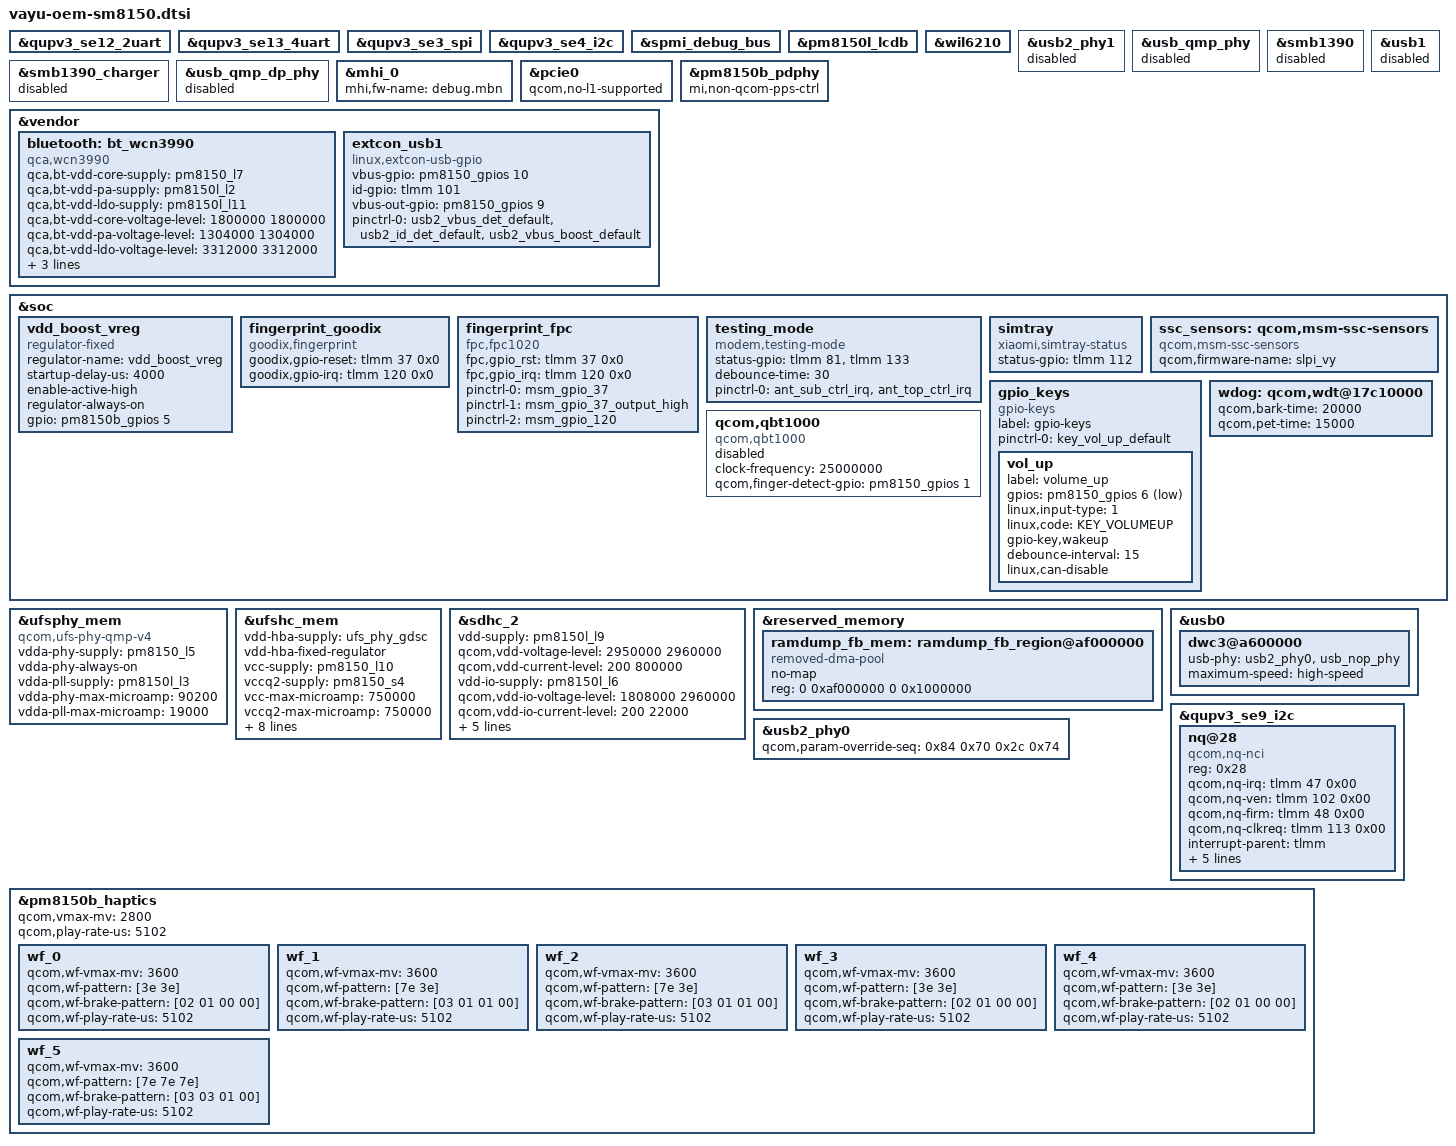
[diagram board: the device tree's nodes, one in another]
/* Copyright (c) 2017-2018, The Linux Foundation. All rights reserved.
 *
 * This program is free software; you can redistribute it and/or modify
 * it under the terms of the GNU General Public License version 2 and
 * only version 2 as published by the Free Software Foundation.
 *
 * This program is distributed in the hope that it will be useful,
 * but WITHOUT ANY WARRANTY; without even the implied warranty of
 * MERCHANTABILITY or FITNESS FOR A PARTICULAR PURPOSE.  See the
 * GNU General Public License for more details.
 */

#include <dt-bindings/gpio/gpio.h>
#include <dt-bindings/input/input.h>

#include "../../sm8150-pmic-overlay.dtsi"
#include "../../sm8150-sde-display.dtsi"

#include "vayu-oem-audio-overlay.dtsi"
#include "vayu-oem-thermal-overlay.dtsi"
#include "vayu-oem-touchscreen-overlay.dtsi"
#include "vayu-oem-sde-overlay.dtsi"
#include "vayu-oem-charger.dtsi"
#include "vayu-oem-leds.dtsi"

#include "vayu-oem-pinctrl.dtsi"
#include "vayu-oem-sm8150-camera-sensor-mtp.dtsi"

&qupv3_se12_2uart {
	status = "ok";
};

&qupv3_se13_4uart {
	status = "ok";
};

&qupv3_se3_spi {
	status = "ok";
};

&qupv3_se4_i2c {
	status = "ok";
};

&spmi_debug_bus {
	status = "ok";
};

&pm8150l_lcdb {
	status = "ok";
};

&wil6210 {
	status = "ok";
};

&usb2_phy1 {
	status = "ok";
};

&usb_qmp_phy {
	status = "ok";
};

&smb1390 {
	status = "disabled";
};

&smb1390_charger {
	status = "disabled";
};

&usb_qmp_dp_phy {
	status = "disabled";
};

&usb1 {
	status = "disabled";
};

&usb2_phy1 {
	status = "disabled";
};

&usb_qmp_phy {
	status = "disabled";
};

&mhi_0 {
	mhi,fw-name = "debug.mbn";
};

&pcie0 {
	qcom,no-l1-supported;
};

&pm8150b_pdphy {
	mi,non-qcom-pps-ctrl;
};

&vendor {

	bluetooth: bt_wcn3990 {
		compatible = "qca,wcn3990";
		qca,bt-vdd-core-supply = <&pm8150_l7>;
		qca,bt-vdd-pa-supply = <&pm8150l_l2>;
		qca,bt-vdd-ldo-supply = <&pm8150l_l11>;

		qca,bt-vdd-core-voltage-level = <1800000 1800000>;
		qca,bt-vdd-pa-voltage-level = <1304000 1304000>;
		qca,bt-vdd-ldo-voltage-level = <3312000 3312000>;

		qca,bt-vdd-core-current-level = <0>; /* LPM/PFM */
		qca,bt-vdd-pa-current-level = <0>; /* LPM/PFM */
		qca,bt-vdd-ldo-current-level = <0>; /* LPM/PFM */
	};

	extcon_usb1: extcon_usb1 {
		compatible = "linux,extcon-usb-gpio";
		vbus-gpio = <&pm8150_gpios 10 GPIO_ACTIVE_HIGH>;
		id-gpio = <&tlmm 101 GPIO_ACTIVE_HIGH>;
		vbus-out-gpio = <&pm8150_gpios 9 GPIO_ACTIVE_HIGH>;

		pinctrl-names = "default";
		pinctrl-0 = <&usb2_vbus_det_default
			     &usb2_id_det_default
			     &usb2_vbus_boost_default>;
	};
};

&soc {

	vdd_boost_vreg: vdd_boost_vreg {
		compatible = "regulator-fixed";
		regulator-name = "vdd_boost_vreg";
		startup-delay-us = <4000>;
		enable-active-high;
		regulator-always-on;
		gpio = <&pm8150b_gpios 5 0>;
	 };

	fingerprint_goodix {
		compatible = "goodix,fingerprint";
		goodix,gpio-reset = <&tlmm 37 0x0>;
		goodix,gpio-irq = <&tlmm 120 0x0>;
		//goodix.gpio_pwr = <&tlmm 125 0x0>;
		//fp_vdd_vreg = <&pm8150l_l7>;
		status = "ok";
	};

	fingerprint_fpc {
			compatible = "fpc,fpc1020";
			fpc,gpio_rst    = <&tlmm 37 0x0>;
			fpc,gpio_irq    = <&tlmm 120 0x0>;
			pinctrl-names = "fpc1020_reset_reset",
					"fpc1020_reset_active",
					"fpc1020_irq_active";

			pinctrl-0 = <&msm_gpio_37>;
			pinctrl-1 = <&msm_gpio_37_output_high>;
			pinctrl-2 = <&msm_gpio_120>;
			status = "ok";
	};

	testing_mode {
		compatible = "modem,testing-mode";
		status-gpio = <&tlmm 81 0x00>,
                      <&tlmm 133 0x00>;
		debounce-time = <30>;
		pinctrl-names = "default";
		pinctrl-0 = <&ant_sub_ctrl_irq &ant_top_ctrl_irq>;
	};

	simtray {
		compatible = "xiaomi,simtray-status";
		status-gpio = <&tlmm 112 0x00>;
	};

	ssc_sensors: qcom,msm-ssc-sensors {
		compatible = "qcom,msm-ssc-sensors";
		status = "ok";
		qcom,firmware-name = "slpi_vy";
	};

	gpio_keys {
		compatible = "gpio-keys";
		label = "gpio-keys";

		pinctrl-names = "default";
		pinctrl-0 = <&key_vol_up_default>;

		vol_up {
			label = "volume_up";
			gpios = <&pm8150_gpios 6 GPIO_ACTIVE_LOW>;
			linux,input-type = <1>;
			linux,code = <KEY_VOLUMEUP>;
			gpio-key,wakeup;
			debounce-interval = <15>;
			linux,can-disable;
		};

	};

	qcom,qbt1000 {
		compatible = "qcom,qbt1000";
		clock-names = "core", "iface";
		clock-frequency = <25000000>;
/*		qcom,ipc-gpio = <&tlmm 118 0>; */
		qcom,finger-detect-gpio = <&pm8150_gpios 1 0>;
		status = "disabled";
	};

	wdog: qcom,wdt@17c10000 {
		qcom,bark-time = <20000>;
		qcom,pet-time = <15000>;
	};
};

&ufsphy_mem {
	compatible = "qcom,ufs-phy-qmp-v4";

	vdda-phy-supply = <&pm8150_l5>;
	vdda-phy-always-on;
	vdda-pll-supply = <&pm8150l_l3>;
	vdda-phy-max-microamp = <90200>;
	vdda-pll-max-microamp = <19000>;

	status = "ok";
};

&ufshc_mem {
	vdd-hba-supply = <&ufs_phy_gdsc>;
	vdd-hba-fixed-regulator;
	vcc-supply = <&pm8150_l10>;
	vccq2-supply = <&pm8150_s4>;
	vcc-max-microamp = <750000>;
	vccq2-max-microamp = <750000>;

	qcom,vddp-ref-clk-supply = <&pm8150_l9>;
	qcom,vddp-ref-clk-max-microamp = <100>;

	vcc-voltage-level = <2504000 2950000>;
	vcc-low-voltage-sup;
	qcom,vccq-parent-supply = <&pm8150l_s8>;
	qcom,vccq-parent-max-microamp = <210000>;
	vccq-supply = <&pm8150_l9>;
	vccq-max-microamp = <700000>;

	status = "ok";
};

&sdhc_2 {
	vdd-supply = <&pm8150l_l9>;
	qcom,vdd-voltage-level = <2950000 2960000>;
	qcom,vdd-current-level = <200 800000>;

	vdd-io-supply = <&pm8150l_l6>;
	qcom,vdd-io-voltage-level = <1808000 2960000>;
	qcom,vdd-io-current-level = <200 22000>;

	pinctrl-names = "active", "sleep";
	pinctrl-0 = <&sdc2_clk_on  &sdc2_cmd_on &sdc2_data_on &storage_cd>;
	pinctrl-1 = <&sdc2_clk_off &sdc2_cmd_off &sdc2_data_off &storage_cd>;

	cd-gpios = <&tlmm 96 GPIO_ACTIVE_HIGH>;

	status = "ok";
};

&reserved_memory {
	ramdump_fb_mem: ramdump_fb_region@af000000 {
		compatible = "removed-dma-pool";
		no-map;
		reg = <0 0xaf000000 0 0x1000000>;
	};
};

&usb0 {
	dwc3@a600000 {
		usb-phy = <&usb2_phy0>, <&usb_nop_phy>;
		maximum-speed = "high-speed";
	};
};

&usb2_phy0 {
	qcom,param-override-seq =
		<0x84 0x70
		 0x2c 0x74>;
};

&qupv3_se9_i2c {
	status = "ok";
	nq@28 {
		compatible = "qcom,nq-nci";
		reg = <0x28>;
		qcom,nq-irq = <&tlmm 47 0x00>;
		qcom,nq-ven = <&tlmm 102 0x00>;
		qcom,nq-firm = <&tlmm 48 0x00>;
		qcom,nq-clkreq = <&tlmm 113 0x00>;
		//qcom,nq-esepwr = <&tlmm 42 0x00>;
		interrupt-parent = <&tlmm>;
		interrupts = <47 0>;
		interrupt-names = "nfc_irq";
		pinctrl-names = "nfc_active", "nfc_suspend";
		pinctrl-0 = <&nfc_int_active &nfc_enable_active
					&nfc_clk_req_active>;
		pinctrl-1 = <&nfc_int_suspend &nfc_enable_suspend
					&nfc_clk_req_suspend>;
	};
};

&pm8150b_haptics {
	qcom,vmax-mv = <2800>;
	qcom,play-rate-us = <5102>;

	wf_0 {
		/* CLICK */
		qcom,wf-vmax-mv = <3600>;
		qcom,wf-pattern = [3e 3e];
		qcom,wf-brake-pattern = [02 01 00 00];
		qcom,wf-play-rate-us = <5102>;
	};
	wf_1 {
		/* DOUBLE CLICK */
		qcom,wf-vmax-mv = <3600>;
		qcom,wf-pattern = [7e 3e];
		qcom,wf-brake-pattern = [03 01 01 00];
		qcom,wf-play-rate-us = <5102>;
	};
	wf_2 {
		/* TICK */
		qcom,wf-vmax-mv = <3600>;
		qcom,wf-pattern = [7e 3e];
		qcom,wf-brake-pattern = [03 01 01 00];
		qcom,wf-play-rate-us = <5102>;
	};
	wf_3 {
		/* THUD */
		qcom,wf-vmax-mv = <3600>;
		qcom,wf-pattern = [3e 3e];
		qcom,wf-brake-pattern = [02 01 00 00];
		qcom,wf-play-rate-us = <5102>;
	};
	wf_4 {
		/* POP */
		qcom,wf-vmax-mv = <3600>;
		qcom,wf-pattern = [3e 3e];
		qcom,wf-brake-pattern = [02 01 00 00];
		qcom,wf-play-rate-us = <5102>;
	};
	wf_5 {
		/* HEAVY CLICK */
		qcom,wf-vmax-mv = <3600>;
		qcom,wf-pattern = [7e 7e 7e];
		qcom,wf-brake-pattern = [03 03 01 00];
		qcom,wf-play-rate-us = <5102>;
	};
};
